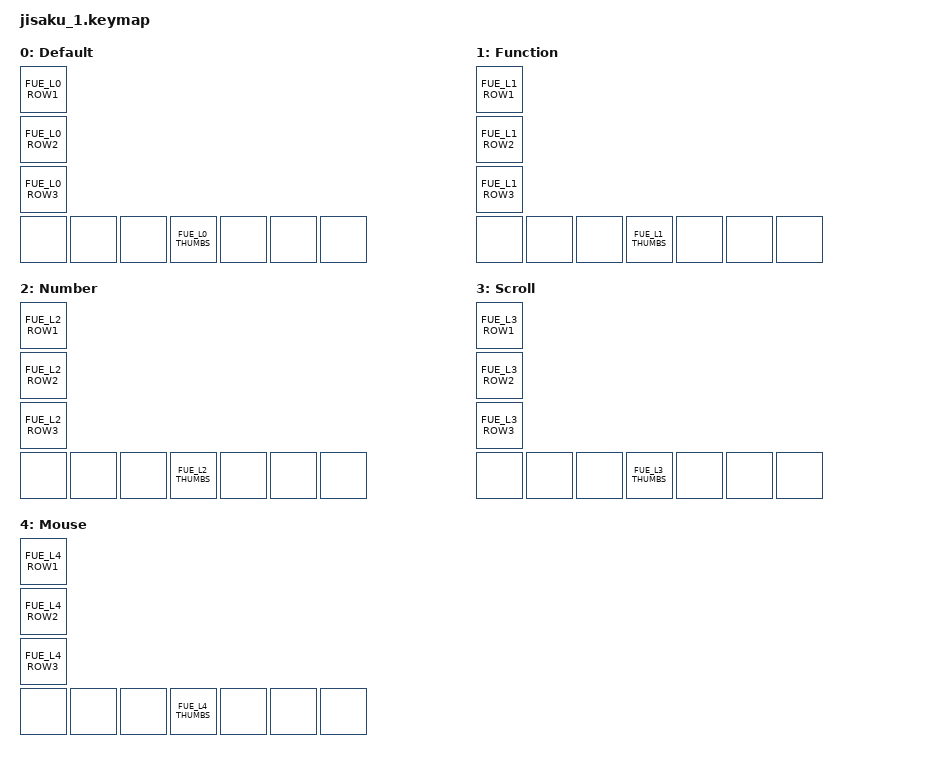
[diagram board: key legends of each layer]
/*
 * jisaku_1 キーマップ(ラッパー)
 *
 * ★実際のキー割り当ては共通リポジトリで定義★
 *   https://github.com/bakajaan/zmk-keymap-common
 *   include/fue/keymap34.dtsi
 * キーマップ変更は上記ファイルを編集すること。
 *
 * このファイルは共通34キー定義を40キーマトリクスへ展開するだけ。
 * 最下段外側3キー×2はaerogu34との統一のため全レイヤーで&none。
 */

/* ランタイムマクロ挙動 (&rmacro) の定義。DYA StudioのMacro & Comboタブから
 * キーへ割り当てる際に使用 (zmk-feature-runtime-macro 2026-07-26追加) */
#include <behaviors/runtime_macro.dtsi>

#include <fue/keymap34.dtsi>

/ {
    keymap {
        compatible = "zmk,keymap";

        default_layer {
            display-name = "Default";
            bindings = <
FUE_L0_ROW1
FUE_L0_ROW2
FUE_L0_ROW3
&none &none &none FUE_L0_THUMBS &none &none &none
            >;
        };

        function_layer {
            display-name = "Function";
            bindings = <
FUE_L1_ROW1
FUE_L1_ROW2
FUE_L1_ROW3
&none &none &none FUE_L1_THUMBS &none &none &none
            >;
        };

        number_layer {
            display-name = "Number";
            bindings = <
FUE_L2_ROW1
FUE_L2_ROW2
FUE_L2_ROW3
&none &none &none FUE_L2_THUMBS &none &none &none
            >;
        };

        scroll_layer {
            display-name = "Scroll";
            bindings = <
FUE_L3_ROW1
FUE_L3_ROW2
FUE_L3_ROW3
&none &none &none FUE_L3_THUMBS &none &none &none
            >;
        };

        mouse_layer {
            display-name = "Mouse";
            bindings = <
FUE_L4_ROW1
FUE_L4_ROW2
FUE_L4_ROW3
&none &none &none FUE_L4_THUMBS &none &none &none
            >;
        };
    };
};
